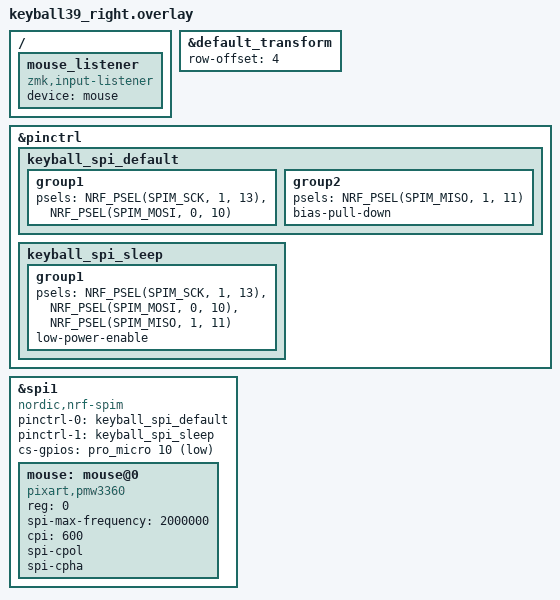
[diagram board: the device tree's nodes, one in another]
// zmk/app/boards/shields/keyball39/keyball39_right.overlay
#include "keyball39.dtsi"
#include <zephyr/dt-bindings/pinctrl/nrf-pinctrl.h>

&default_transform { // The matrix transform for this board is 4 rows over because the left half is 4 rows tall according to the matrix.
    row-offset = <4>;
};

&pinctrl {
    keyball_spi_default: keyball_spi_default {
        group1 {
            psels = <NRF_PSEL(SPIM_SCK, 1, 13)>,
                    <NRF_PSEL(SPIM_MOSI, 0, 10)>;
        };
        group2 {
            psels = <NRF_PSEL(SPIM_MISO, 1, 11)>;
            bias-pull-down;
        };
    };

    keyball_spi_sleep: keyball_spi_sleep {
        group1 {
            psels = <NRF_PSEL(SPIM_SCK, 1, 13)>,
                    <NRF_PSEL(SPIM_MOSI, 0, 10)>,
                    <NRF_PSEL(SPIM_MISO, 1, 11)>;
            low-power-enable;
        };
    };
};

&spi1 {
    compatible = "nordic,nrf-spim";
    status = "okay";
    pinctrl-0 = <&keyball_spi_default>;
    pinctrl-1 = <&keyball_spi_sleep>;
    pinctrl-names = "default", "sleep";
    cs-gpios = <&pro_micro 10 GPIO_ACTIVE_LOW>;
    mouse: mouse@0 {
        compatible = "pixart,pmw3360";
        status = "okay";
        reg = <0>;
        spi-max-frequency = <2000000>;
        cpi = <600>;
        spi-cpol;
        spi-cpha;
        // Recommended: wire the PMW3360 MOTION pin to a spare GPIO and add
        // irq-gpios here to leave polled mode. Example:
        // irq-gpios = <&pro_micro X (GPIO_ACTIVE_LOW | GPIO_PULL_UP)>;
    };
};

/ {
    mouse_listener {
        compatible = "zmk,input-listener";
        device = <&mouse>;
    };
};
